# AT32UC3C2256C device description
Architecture: AVR32_UC3; Family: AVR UC3
Registers are 32-bit, read-write, reset 0x0 unless marked. A register's access mark holds for its fields unless they carry their own. Offsets are from the block's base; [hi:lo] are bit positions; {n}, {i} and the like mark numbered series; 'fields as' and 'values as' point back to an identical list.

## CORE — AVR32UC3 CPU
Instances: CORE 0 in sysreg
Parameters: EVBA_OFFSET_BREAKPOINT=28, EVBA_OFFSET_BUS_ERROR_DATA=8, EVBA_OFFSET_BUS_ERROR_INSTR=12, EVBA_OFFSET_COP_ABSENT=48, EVBA_OFFSET_DATA_ADDR_R=52, EVBA_OFFSET_DATA_ADDR_W=56, EVBA_OFFSET_DTLB_MISS_R=96, EVBA_OFFSET_DTLB_MISS_W=112, EVBA_OFFSET_DTLB_MODIFIED=68, EVBA_OFFSET_DTLB_PROT_R=60, EVBA_OFFSET_DTLB_PROT_W=64, EVBA_OFFSET_FLOATING_POINT=44, EVBA_OFFSET_ILLEGAL_OPCODE=32, EVBA_OFFSET_INSTR_ADDR=20, EVBA_OFFSET_ITLB_MISS=80, EVBA_OFFSET_ITLB_PROT=24, EVBA_OFFSET_NMI=16, EVBA_OFFSET_PRIVILEGE_VIOL=40, EVBA_OFFSET_SCALL=256, EVBA_OFFSET_TLB_MULTIPLE=4, EVBA_OFFSET_UNIMPLEMENTED=36, EVBA_OFFSET_UNRECOVERABLE=0, RESET_VECTOR=0x80000000 /* Comment to make sure this value is not mistaken for a signed int */
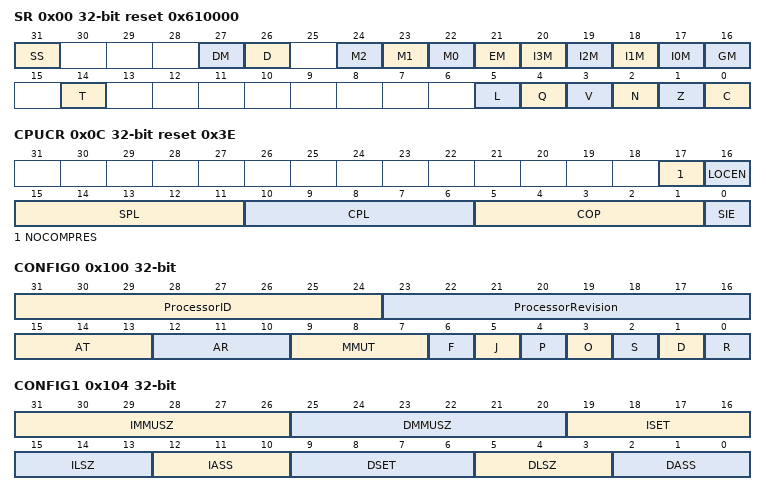
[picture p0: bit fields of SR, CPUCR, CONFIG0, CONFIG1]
0x00 SR reset 0x610000 — Status Register
  [31] SS — Secure State
  [27] DM — Debug State Mask
  [26] D — Debug state
  [24] M2 — Mode bit 2
  [23] M1 — Mode bit 1
  [22] M0 — Mode bit 0
  [21] EM — Exception Mask
  [n+17] I{n}M (n=0..3) — Interrupt Level {n} Mask
  [16] GM — Global Interrupt Mask
  [14] T — Scratch
  [5] L — Lock
  [4] Q — Saturation
  [3] V — Overflow
  [2] N — Sign
  [1] Z — Zero
  [0] C — Carry
0x04 EVBA — Exception Vector Base Address
0x08 ACBA — Application Call Base Address
0x0C CPUCR reset 0x3E — CPU Control Register
  [17] NOCOMPRES — No COUNT reset on COMPARE match
  [16] LOCEN — Local Bus Enable
  [15:11] SPL — Slave Pending Limit
  [10:6] CPL — CPU Pending Limit
  [5:1] COP — CPU Ownership Period
  [0] SIE — Slave Interface
0x10 ECR ro — Exception Cause Register
  [31:0] ECR — Exception cause
    0=UNRECOVERABLE; 1=TLB_MULTIPLE; 2=BUS_ERROR_WRITE; 3=BUS_ERROR_READ; 4=NMI; 5=ADDR_ALIGN_X; 6=PROTECTION_X; 7=DEBUG; 8=ILLEGAL_OPCODE; 9=UNIMPL_INSTRUCTION; 10=PRIVILEGE_VIOLATION; 11=FPE; 12=COPROC_ABSENT; 13=ADDR_ALIGN_R; 14=ADDR_ALIGN_W; 15=PROTECTION_R; 16=PROTECTION_W; 17=DTLB_MODIFIED; 20=TLB_MISS_X; 24=TLB_MISS_R; 28=TLB_MISS_W
0x30 RSR_DBG — Return Status Register for Debug mode
0x50 RAR_DBG — Return Address Register for Debug mode
0x100 CONFIG0 ro reset not defined — Configuration Register 0
  [31:24] ProcessorID
  [23:16] ProcessorRevision — Processor Revison
  [15:13] AT — Architecture Type
  [12:10] AR — Architecture Revision
  [9:7] MMUT — MMU Type
  [6] F — Floating-point unit implemented
  [5] J — Java extension implemented
  [4] P — Performance counters implemented
  [3] O — On-chip debug implemented
  [2] S — SIMD instructions implemented
  [1] D — DSP instructions implemented
  [0] R — Memory Read-Modify-Write instructions implemented
0x104 CONFIG1 ro reset not defined — Configuration Register 1
  [31:26] IMMUSZ — IMMU Size
  [25:20] DMMUSZ — DMMU Size
  [19:16] ISET — Number of sets in the ICACHE
  [15:13] ILSZ — Line size in ICACHE
  [12:10] IASS — Associativity of ICACHE
  [9:6] DSET — Number of sets in the DCACHE
  [5:3] DLSZ — Line size in DCACHE
  [2:0] DASS — Associativity of DCACHE
0x108 COUNT — Cycle Counter Register
0x10C COMPARE
0x13C BEAR — Bus Error Address Register
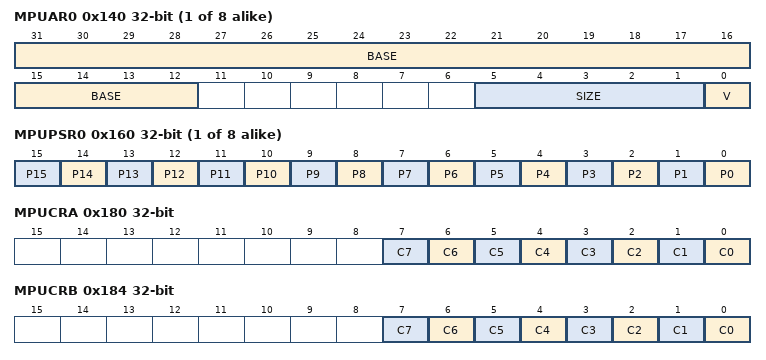
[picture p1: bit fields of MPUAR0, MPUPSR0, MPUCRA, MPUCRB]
{0x140+4i} MPUAR{i} (i=0..7) — MPU Address Register {i}
  [31:12] BASE — Base address of the region
  [5:1] SIZE — Size of the region
  [0] V — Valid
{0x160+4i} MPUPSR{i} (i=0..7) — MPU Permission Select Register {i}
  [n] P{n} (n=0..15) — Privilege Select Subregion {n}
0x180 MPUCRA — MPU Cacheable Register A
  [n] C{n} (n=0..7) — Cacheable region {n}
0x184 MPUCRB — MPU Cacheable Register B
  [n] C{n} (n=0..7) — Cacheable region {n}
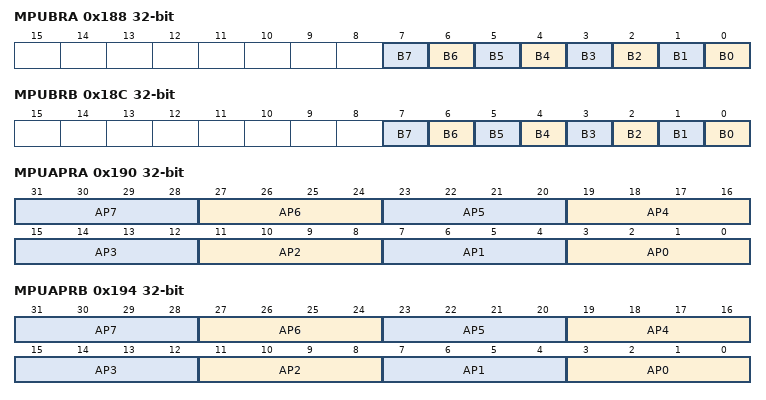
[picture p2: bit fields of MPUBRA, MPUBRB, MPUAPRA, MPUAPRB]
0x188 MPUBRA — MPU Bufferable Register A
  [n] B{n} (n=0..7) — Bufferable region {n}
0x18C MPUBRB — MPU Bufferable Register B
  [n] B{n} (n=0..7) — Bufferable region {n}
0x190 MPUAPRA — MPU Access Permission Register A
  [all] fields
    1=EXECUTE; 2=WRITE; 4=USER; 8=SUP_WRITE
  [4n+3:4n] AP{n} (n=0..7) — Access Permissions for MPU region {n}
0x194 MPUAPRB — MPU Access Permission Register B
  fields as MPUAPRA
0x198 MPUCR — MPU Control Register
  [0] E — MPU Enable
0x19C SS_STATUS ro — Secure State Status Register
0x1A0 SS_ADRF — Secure State Size Flash Register
0x1A4 SS_ADRR — Secure State Size RAM Register
0x1A8 SS_ADR0 — Secure State Size Mem0 Register
0x1AC SS_ADR1 — Secure State Size Mem1 Register
0x1B0 SS_SP_SYS — Secure State SP_SYS Register
0x1B4 SS_SP_APP — Secure State SP_APP Register
0x1B8 SS_RAR — Secure State Return Address Register
0x1BC SS_RSR — Secure State Return Status Register
0x3E0 MSU_ADDRHI — Memory Service Unit Address High Register
  [3:0] ADDRHI — Address High Part
0x3E4 MSU_ADDRLO — Memory Service Unit Address Low Register
  [31:2] ADDRLO — Address Low Part
0x3E8 MSU_LENGTH — Memory Service Unit Length Register
  [31:2] LENGTH — Length value
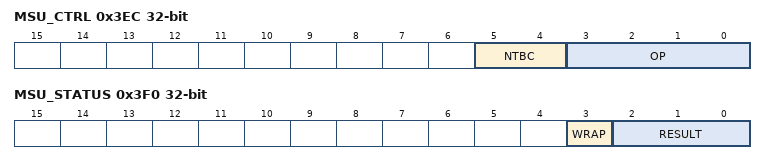
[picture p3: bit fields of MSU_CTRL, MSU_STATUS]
0x3EC MSU_CTRL — Memory Service Unit Control Register
  [5:4] NTBC — NanoTrace Buffer Control
    0=OVER; 1=DISABLE; 2=BREAK_STOP; 3=BREAK_FLUSH
  [3:0] OP — Requested Operation
    0=NONE; 1=CRC; 2=NTRACE; 3=MBIST
0x3F0 MSU_STATUS ro — Memory Service Unit Status Register
  [3] WRAP
  [2:0] RESULT — Result of current or last operation
    0=DONE; 1=BUSY; 2=NOT_IMPL; 3=BUS_ERR; 4=FAILED; 5=LOCKED; 6=CANCELED
0x3F4 MSU_DATA — Memory Service Unit Data Register
  [31:0] DATA — Generic Data Register
0x3F8 MSU_TAIL — Memory Service Unit Tail Register
  [31:2] TAIL — Tail Address Register for NanoTrace buffer
